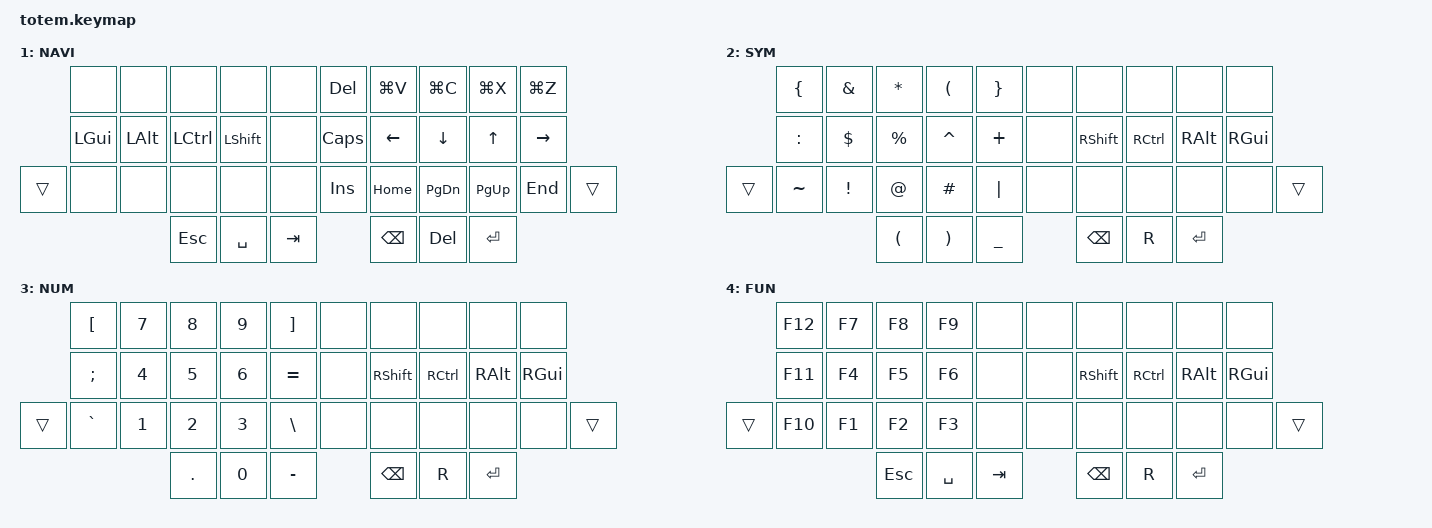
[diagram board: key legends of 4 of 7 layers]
//
//                                                        ▀▀▀▀▀     ▀▀▀▀▀          ▀▀█▀▀
//                                                        ▄▀▀▀▄  ▄  ▄▀▀▀▄  ▄  ▄▀▀▀▄  █  ▄▀▀▀▄
//                                                        █   █  █  █   █  █  █   █  █  █   █
//                                                         ▀▀▀   █   ▀▀▀   █   ▀▀▀   ▀   ▀▀▀
//                                                               █      ▄▄▄█▄▄▄    █   █  
//                                                               ▀      █  █  █     █▄█
//                                                             ▀▀▀▀▀    █  █  █      ▀
//                                                                      ▀  ▀  ▀
//
// ▄▄▄▄▄▄▄▄▄▄▄▄▄▄▄▄▄▄▄▄▄▄▄▄▄▄▄▄▄▄▄▄▄▄▄▄▄▄▄▄▄▄▄▄▄▄▄▄▄▄▄▄▄▄▄▄▄▄▄▄▄▄▄▄▄▄▄▄▄▄▄▄▄▄▄▄▄▄▄▄▄▄▄▄▄▄▄▄▄▄▄▄▄▄▄▄▄▄▄▄▄▄▄▄▄▄▄▄▄▄▄▄▄▄▄▄▄▄▄▄▄▄▄▄▄▄▄▄▄▄▄▄▄▄▄▄▄▄▄▄▄▄▄▄▄▄▄▄▄
       

#include <behaviors.dtsi>
#include <dt-bindings/zmk/keys.h>
#include <dt-bindings/zmk/bt.h>
#include <dt-bindings/zmk/outputs.h>
#define ZMK_POINTING_DEFAULT_MOVE_VAL 1500  // default: 600
#define ZMK_POINTING_DEFAULT_SCRL_VAL 20    // default: 10

#include <dt-bindings/zmk/pointing.h>
// Home row mods macro
#define HRML(k1,k2,k3,k4) &ht LGUI k1 &ht LALT k2  &ht LCTRL k3  &ht LSHFT k4
#define HRMR(k1,k2,k3,k4) &ht RSHFT k1  &ht RCTRL k2  &ht RALT k3  &ht RGUI k4

#define BASE 0
#define NAV  1
#define SYM  2
#define NUM  3
#define FUN  4
#define MOU  5
#define MED  6


/ {
    behaviors {
        ht: hold_tap {
            compatible = "zmk,behavior-hold-tap";
            #binding-cells = <2>;
            flavor = "tap-preferred";
            tapping-term-ms = <220>;
            quick-tap-ms = <150>;
            require-prior-idle-ms = <100>;
            bindings = <&kp>, <&kp>;
        };
    };

    combos {
        compatible = "zmk,combos";
        combo_z {
                timeout-ms = <50>;
                key-positions = <0 1>;
                bindings = <&kp Z>;
        };

        combo_q {
                timeout-ms = <50>;
                key-positions = <1 3>;
                bindings = <&kp Q>;
        };

    };

        keymap {
                compatible = "zmk,keymap";
// ▄▄▄▄▄▄▄▄▄▄▄▄▄▄▄▄▄▄▄▄▄▄▄▄▄▄▄▄▄▄▄▄▄▄▄▄▄▄▄▄▄▄▄▄▄▄▄▄▄▄▄▄▄▄▄▄▄▄▄▄▄▄▄▄▄▄▄▄▄▄▄▄▄▄▄▄▄▄▄▄▄▄▄▄▄▄▄▄▄▄▄▄▄▄▄▄▄▄▄▄▄▄▄▄▄▄▄▄▄▄▄▄▄▄▄▄▄▄▄▄▄▄▄▄▄▄▄▄▄▄▄▄▄▄▄▄▄▄▄▄▄▄▄▄▄▄▄▄▄

                base_layer {
// ┏━━━━━━━━━━━━━━━━━━━━━━━━━━━━━━━━━━━━━━━┓
label= "BASE"                              ;
// ┗━━━━━━━━━━━━━━━━━━━━━━━━━━━━━━━━━━━━━━━┛
//             ┏━━━━━━━━━━━┳━━━━━━━━━━━┳━━━━━━━━━━━┳━━━━━━━━━━━┳━━━━━━━━━━━┓   ┏━━━━━━━━━━━┳━━━━━━━━━━━┳━━━━━━━━━━━┳━━━━━━━━━━━┳━━━━━━━━━━━┓
//             ┃     Q     ┃     W     ┃     F     ┃     P     ┃     G     ┃   ┃     J     ┃     L     ┃     U     ┃     Y     ┃     ;     ┃
//             ┣━━━━━━━━━━━╋━━━━━━━━━━━╋━━━━━━━━━━━╋━━━━━━━━━━━╋━━━━━━━━━━━┫   ┣━━━━━━━━━━━╋━━━━━━━━━━━╋━━━━━━━━━━━╋━━━━━━━━━━━╋━━━━━━━━━━━┫
//             ┃     A     ┃     R     ┃     S     ┃     T     ┃     D     ┃   ┃     H     ┃     N     ┃     E     ┃     I     ┃     O     ┃
// ┏━━━━━━━━━━━╋━━━━━━━━━━━╋━━━━━━━━━━━╋━━━━━━━━━━━╋━━━━━━━━━━━╋━━━━━━━━━━━┫   ┣━━━━━━━━━━━╋━━━━━━━━━━━╋━━━━━━━━━━━╋━━━━━━━━━━━╋━━━━━━━━━━━╋━━━━━━━━━━━┓
// ┃           ┃     Z     ┃     X     ┃     C     ┃     V     ┃     B     ┃   ┃     K     ┃     M     ┃     ,     ┃     .     ┃     /     ┃           ┃
// ┗━━━━━━━━━━━┻━━━━━━━━━━━┻━━━━━━━━━━━╋━━━━━━━━━━━╋━━━━━━━━━━━╋━━━━━━━━━━━┫   ┣━━━━━━━━━━━╋━━━━━━━━━━━╋━━━━━━━━━━━╋━━━━━━━━━━━┻━━━━━━━━━━━┻━━━━━━━━━━━┛
//                                     ┃           ┃    TAB    ┃    SPC    ┃   ┃   ENTER   ┃   BSPC    ┃           ┃
//                                     ┗━━━━━━━━━━━┻━━━━━━━━━━━┻━━━━━━━━━━━┛   ┗━━━━━━━━━━━┻━━━━━━━━━━━┻━━━━━━━━━━━┛
 bindings = <
// ╷           ╷           ╷           ╷           ╷           ╷           ╷   ╷           ╷           ╷           ╷           ╷           ╷           ╷

                &kp X      &kp W      &kp M      &kp G      &kp DQT             &kp HASH       &kp DOT     &kp SQT     &kp J      &kp B
                HRML(S,     C,         N,           T)          &kp K           &kp COMMA      HRMR(A,       E,          I,          H)
    &kp Z       &kp V      &kp P      &kp L      &kp D      &kp FSLH            &kp MINUS      &kp U       &kp O       &kp Y      &kp F   &kp Q
                                        &lt MED ESC     &lt NAV SPC     &kp TAB      &lt SYM BSPC  &lt NUM R    &lt FUN ENTER
                        >;
                };

// ▄▄▄▄▄▄▄▄▄▄▄▄▄▄▄▄▄▄▄▄▄▄▄▄▄▄▄▄▄▄▄▄▄▄▄▄▄▄▄▄▄▄▄▄▄▄▄▄▄▄▄▄▄▄▄▄▄▄▄▄▄▄▄▄▄▄▄▄▄▄▄▄▄▄▄▄▄▄▄▄▄▄▄▄▄▄▄▄▄▄▄▄▄▄▄▄▄▄▄▄▄▄▄▄▄▄▄▄▄▄▄▄▄▄▄▄▄▄▄▄▄▄▄▄▄▄▄▄▄▄▄▄▄▄▄▄▄▄▄▄▄▄▄▄▄▄▄▄▄


                nav_layer {
// ┏━━━━━━━━━━━━━━━━━━━━━━━━━━━━━━━━━━━━━━━┓
label= "NAVI"                              ;
// ┗━━━━━━━━━━━━━━━━━━━━━━━━━━━━━━━━━━━━━━━┛
//             ┏━━━━━━━━━━━┳━━━━━━━━━━━┳━━━━━━━━━━━┳━━━━━━━━━━━┳━━━━━━━━━━━┓   ┏━━━━━━━━━━━┳━━━━━━━━━━━┳━━━━━━━━━━━┳━━━━━━━━━━━┳━━━━━━━━━━━┓
//             ┃           ┃           ┃     UP    ┃           ┃     {     ┃   ┃     }     ┃     7     ┃     8     ┃     9     ┃     +     ┃
//             ┣━━━━━━━━━━━╋━━━━━━━━━━━╋━━━━━━━━━━━╋━━━━━━━━━━━╋━━━━━━━━━━━┫   ┣━━━━━━━━━━━╋━━━━━━━━━━━╋━━━━━━━━━━━╋━━━━━━━━━━━╋━━━━━━━━━━━┫
//             ┃   SHIFT   ┃   LEFT    ┃    DOWN   ┃   RIGHT   ┃     [     ┃   ┃     ]     ┃     4     ┃     5     ┃     6     ┃     -     ┃
// ┏━━━━━━━━━━━╋━━━━━━━━━━━╋━━━━━━━━━━━╋━━━━━━━━━━━╋━━━━━━━━━━━╋━━━━━━━━━━━┫   ┣━━━━━━━━━━━╋━━━━━━━━━━━╋━━━━━━━━━━━╋━━━━━━━━━━━╋━━━━━━━━━━━╋━━━━━━━━━━━┓
// ┃           ┃           ┃   P UP    ┃  C LOCK   ┃  P DOWN   ┃     (     ┃   ┃     )     ┃     1     ┃     2     ┃     3     ┃     *     ┃           ┃
// ┗━━━━━━━━━━━┻━━━━━━━━━━━┻━━━━━━━━━━━╋━━━━━━━━━━━╋━━━━━━━━━━━╋━━━━━━━━━━━┫   ┣━━━━━━━━━━━╋━━━━━━━━━━━╋━━━━━━━━━━━╋━━━━━━━━━━━┻━━━━━━━━━━━┻━━━━━━━━━━━┛
//                                     ┃           ┃    TAB    ┃    SPC    ┃   ┃    DEL    ┃     0     ┃           ┃
//                                     ┗━━━━━━━━━━━┻━━━━━━━━━━━┻━━━━━━━━━━━┛   ┗━━━━━━━━━━━┻━━━━━━━━━━━┻━━━━━━━━━━━┛
 bindings = <
// ╷           ╷           ╷           ╷           ╷           ╷           ╷   ╷           ╷           ╷           ╷           ╷           ╷           ╷

                &none        &none     &none     &none       &none         &kp DEL  &kp LG(V)  &kp LG(C)  &kp LG(X)  &kp LG(Z)
                &kp LGUI   &kp LALT   &kp LCTRL   &kp LSHFT   &none         &kp CAPS   &kp LEFT   &kp DOWN    &kp UP    &kp RIGHT
    &trans      &none        &none     &none     &none       &none         &kp INS     &kp HOME  &kp PG_DN   &kp PG_UP   &kp END &trans      
                                        &kp ESC      &kp SPC      &kp TAB          &kp BSPC     &kp DEL   &kp ENTER      
                        >;
                };

// ▄▄▄▄▄▄▄▄▄▄▄▄▄▄▄▄▄▄▄▄▄▄▄▄▄▄▄▄▄▄▄▄▄▄▄▄▄▄▄▄▄▄▄▄▄▄▄▄▄▄▄▄▄▄▄▄▄▄▄▄▄▄▄▄▄▄▄▄▄▄▄▄▄▄▄▄▄▄▄▄▄▄▄▄▄▄▄▄▄▄▄▄▄▄▄▄▄▄▄▄▄▄▄▄▄▄▄▄▄▄▄▄▄▄▄▄▄▄▄▄▄▄▄▄▄▄▄▄▄▄▄▄▄▄▄▄▄▄▄▄▄▄▄▄▄▄▄▄▄


                sim_layer {
// ┏━━━━━━━━━━━━━━━━━━━━━━━━━━━━━━━━━━━━━━━┓
label= "SYM"                               ;
// ┗━━━━━━━━━━━━━━━━━━━━━━━━━━━━━━━━━━━━━━━┛
//             ┏━━━━━━━━━━━┳━━━━━━━━━━━┳━━━━━━━━━━━┳━━━━━━━━━━━┳━━━━━━━━━━━┓   ┏━━━━━━━━━━━┳━━━━━━━━━━━┳━━━━━━━━━━━┳━━━━━━━━━━━┳━━━━━━━━━━━┓
//             ┃     !     ┃     @     ┃     #     ┃     $     ┃     %     ┃   ┃     ˆ     ┃     &     ┃     Ü     ┃     '     ┃     "     ┃
//             ┣━━━━━━━━━━━╋━━━━━━━━━━━╋━━━━━━━━━━━╋━━━━━━━━━━━╋━━━━━━━━━━━┫   ┣━━━━━━━━━━━╋━━━━━━━━━━━╋━━━━━━━━━━━╋━━━━━━━━━━━╋━━━━━━━━━━━┫
//             ┃     Ä     ┃           ┃    SZ     ┃           ┃           ┃   ┃   MUTE    ┃   YEN     ┃   EURO    ┃  POUND    ┃     Ö     ┃
// ┏━━━━━━━━━━━╋━━━━━━━━━━━╋━━━━━━━━━━━╋━━━━━━━━━━━╋━━━━━━━━━━━╋━━━━━━━━━━━┫   ┣━━━━━━━━━━━╋━━━━━━━━━━━╋━━━━━━━━━━━╋━━━━━━━━━━━╋━━━━━━━━━━━╋━━━━━━━━━━━┓
// ┃           ┃  EMAIL1   ┃  EMAIL2   ┃           ┃           ┃           ┃   ┃   VOL-    ┃   VOL+    ┃   LAST    ┃   NEXT    ┃     \     ┃           ┃
// ┗━━━━━━━━━━━┻━━━━━━━━━━━┻━━━━━━━━━━━╋━━━━━━━━━━━╋━━━━━━━━━━━╋━━━━━━━━━━━┫   ┣━━━━━━━━━━━╋━━━━━━━━━━━╋━━━━━━━━━━━╋━━━━━━━━━━━┻━━━━━━━━━━━┻━━━━━━━━━━━┛
//                                     ┃           ┃    GIF    ┃    ADJ    ┃   ┃           ┃           ┃           ┃
//                                     ┗━━━━━━━━━━━┻━━━━━━━━━━━┻━━━━━━━━━━━┛   ┗━━━━━━━━━━━┻━━━━━━━━━━━┻━━━━━━━━━━━┛
 bindings = <
// ╷           ╷           ╷           ╷           ╷           ╷           ╷   ╷           ╷           ╷           ╷           ╷           ╷           ╷

                &kp LBRC    &kp AMPS   &kp ASTRK   &kp LPAR   &kp RBRC            &none        &none     &none     &none       &none      
                &kp COLON   &kp DLLR  &kp PRCNT   &kp CARET &kp PLUS              &none     &kp RSHFT  &kp RCTRL   &kp RALT   &kp RGUI 
    &trans      &kp TILDE   &kp EXCL     &kp AT     &kp HASH     &kp PIPE         &none        &none     &none     &none       &none   &trans         
                                        &kp LPAR      &kp RPAR      &kp UNDER          &kp BSPC      &kp R    &kp ENTER      
                        >;
                };

// ▄▄▄▄▄▄▄▄▄▄▄▄▄▄▄▄▄▄▄▄▄▄▄▄▄▄▄▄▄▄▄▄▄▄▄▄▄▄▄▄▄▄▄▄▄▄▄▄▄▄▄▄▄▄▄▄▄▄▄▄▄▄▄▄▄▄▄▄▄▄▄▄▄▄▄▄▄▄▄▄▄▄▄▄▄▄▄▄▄▄▄▄▄▄▄▄▄▄▄▄▄▄▄▄▄▄▄▄▄▄▄▄▄▄▄▄▄▄▄▄▄▄▄▄▄▄▄▄▄▄▄▄▄▄▄▄▄▄▄▄▄▄▄▄▄▄▄▄▄


                num_layer {
// ┏━━━━━━━━━━━━━━━━━━━━━━━━━━━━━━━━━━━━━━━┓
label= "NUM"                               ;
// ┗━━━━━━━━━━━━━━━━━━━━━━━━━━━━━━━━━━━━━━━┛
//             ┏━━━━━━━━━━━┳━━━━━━━━━━━┳━━━━━━━━━━━┳━━━━━━━━━━━┳━━━━━━━━━━━┓   ┏━━━━━━━━━━━┳━━━━━━━━━━━┳━━━━━━━━━━━┳━━━━━━━━━━━┳━━━━━━━━━━━┓
//             ┃   RESET   ┃ BT CLEAR  ┃  OUT TOG  ┃           ┃           ┃   ┃           ┃    F7     ┃    F8     ┃    F9     ┃    F12    ┃
//             ┣━━━━━━━━━━━╋━━━━━━━━━━━╋━━━━━━━━━━━╋━━━━━━━━━━━╋━━━━━━━━━━━┫   ┣━━━━━━━━━━━╋━━━━━━━━━━━╋━━━━━━━━━━━╋━━━━━━━━━━━╋━━━━━━━━━━━┫
//             ┃ BOOTLOAD  ┃ BT NEXT   ┃           ┃           ┃           ┃   ┃           ┃    F4     ┃    F5     ┃    F6     ┃    F11    ┃
// ┏━━━━━━━━━━━╋━━━━━━━━━━━╋━━━━━━━━━━━╋━━━━━━━━━━━╋━━━━━━━━━━━╋━━━━━━━━━━━┫   ┣━━━━━━━━━━━╋━━━━━━━━━━━╋━━━━━━━━━━━╋━━━━━━━━━━━╋━━━━━━━━━━━╋━━━━━━━━━━━┓
// ┃           ┃           ┃ BT PREV   ┃           ┃           ┃           ┃   ┃           ┃    F1     ┃    F2     ┃    F3     ┃    F10    ┃           ┃
// ┗━━━━━━━━━━━┻━━━━━━━━━━━┻━━━━━━━━━━━╋━━━━━━━━━━━╋━━━━━━━━━━━╋━━━━━━━━━━━┫   ┣━━━━━━━━━━━╋━━━━━━━━━━━╋━━━━━━━━━━━╋━━━━━━━━━━━┻━━━━━━━━━━━┻━━━━━━━━━━━┛
//                                     ┃           ┃           ┃           ┃   ┃           ┃           ┃           ┃
//                                     ┗━━━━━━━━━━━┻━━━━━━━━━━━┻━━━━━━━━━━━┛   ┗━━━━━━━━━━━┻━━━━━━━━━━━┻━━━━━━━━━━━┛
 bindings = <
// ╷           ╷           ╷           ╷           ╷           ╷           ╷   ╷           ╷           ╷           ╷           ╷           ╷           ╷

                &kp LBKT    &kp N7     &kp N8     &kp N9    &kp RBKT          &none     &none     &none     &none     &none
                &kp SEMI    &kp N4     &kp N5     &kp N6    &kp EQUAL          &none    &kp RSHFT   &kp RCTRL  &kp RALT   &kp RGUI  
    &trans      &kp GRAVE   &kp N1     &kp N2       &kp N3    &kp BSLH          &none     &none     &none     &none     &none     &trans         
                                        &kp DOT      &kp N0      &kp MINUS          &kp BSPC      &kp R      &kp ENTER      
                        >;
                };

                fun_layer {
// ┏━━━━━━━━━━━━━━━━━━━━━━━━━━━━━━━━━━━━━━━┓
label= "FUN"                               ;
// ┗━━━━━━━━━━━━━━━━━━━━━━━━━━━━━━━━━━━━━━━┛
//             ┏━━━━━━━━━━━┳━━━━━━━━━━━┳━━━━━━━━━━━┳━━━━━━━━━━━┳━━━━━━━━━━━┓   ┏━━━━━━━━━━━┳━━━━━━━━━━━┳━━━━━━━━━━━┳━━━━━━━━━━━┳━━━━━━━━━━━┓
//             ┃   RESET   ┃ BT CLEAR  ┃  OUT TOG  ┃           ┃           ┃   ┃           ┃    F7     ┃    F8     ┃    F9     ┃    F12    ┃
//             ┣━━━━━━━━━━━╋━━━━━━━━━━━╋━━━━━━━━━━━╋━━━━━━━━━━━╋━━━━━━━━━━━┫   ┣━━━━━━━━━━━╋━━━━━━━━━━━╋━━━━━━━━━━━╋━━━━━━━━━━━╋━━━━━━━━━━━┫
//             ┃ BOOTLOAD  ┃ BT NEXT   ┃           ┃           ┃           ┃   ┃           ┃    F4     ┃    F5     ┃    F6     ┃    F11    ┃
// ┏━━━━━━━━━━━╋━━━━━━━━━━━╋━━━━━━━━━━━╋━━━━━━━━━━━╋━━━━━━━━━━━╋━━━━━━━━━━━┫   ┣━━━━━━━━━━━╋━━━━━━━━━━━╋━━━━━━━━━━━╋━━━━━━━━━━━╋━━━━━━━━━━━╋━━━━━━━━━━━┓
// ┃           ┃           ┃ BT PREV   ┃           ┃           ┃           ┃   ┃           ┃    F1     ┃    F2     ┃    F3     ┃    F10    ┃           ┃
// ┗━━━━━━━━━━━┻━━━━━━━━━━━┻━━━━━━━━━━━╋━━━━━━━━━━━╋━━━━━━━━━━━╋━━━━━━━━━━━┫   ┣━━━━━━━━━━━╋━━━━━━━━━━━╋━━━━━━━━━━━╋━━━━━━━━━━━┻━━━━━━━━━━━┻━━━━━━━━━━━┛
//                                     ┃           ┃           ┃           ┃   ┃           ┃           ┃           ┃
//                                     ┗━━━━━━━━━━━┻━━━━━━━━━━━┻━━━━━━━━━━━┛   ┗━━━━━━━━━━━┻━━━━━━━━━━━┻━━━━━━━━━━━┛
 bindings = <
// ╷           ╷           ╷           ╷           ╷           ╷           ╷   ╷           ╷           ╷           ╷           ╷           ╷           ╷

                &kp F12       &kp F7     &kp F8       &kp F9       &none           &none       &none       &none       &none      &none
                &kp F11       &kp F4     &kp F5       &kp F6       &none           &none     &kp RSHFT    &kp RCTRL   &kp RALT   &kp RGUI  
    &trans      &kp F10       &kp F1     &kp F2       &kp F3       &none           &none       &none       &none       &none      &none     &trans         
                                        &kp ESC      &kp SPC      &kp TAB          &kp BSPC      &kp R      &kp ENTER      
                        >;
                };

                mouse_layer {
// ┏━━━━━━━━━━━━━━━━━━━━━━━━━━━━━━━━━━━━━━━┓
label= "MOU"                               ;
// ┗━━━━━━━━━━━━━━━━━━━━━━━━━━━━━━━━━━━━━━━┛
//             ┏━━━━━━━━━━━┳━━━━━━━━━━━┳━━━━━━━━━━━┳━━━━━━━━━━━┳━━━━━━━━━━━┓   ┏━━━━━━━━━━━┳━━━━━━━━━━━┳━━━━━━━━━━━┳━━━━━━━━━━━┳━━━━━━━━━━━┓
//             ┃   RESET   ┃ BT CLEAR  ┃  OUT TOG  ┃           ┃           ┃   ┃           ┃    F7     ┃    F8     ┃    F9     ┃    F12    ┃
//             ┣━━━━━━━━━━━╋━━━━━━━━━━━╋━━━━━━━━━━━╋━━━━━━━━━━━╋━━━━━━━━━━━┫   ┣━━━━━━━━━━━╋━━━━━━━━━━━╋━━━━━━━━━━━╋━━━━━━━━━━━╋━━━━━━━━━━━┫
//             ┃ BOOTLOAD  ┃ BT NEXT   ┃           ┃           ┃           ┃   ┃           ┃    F4     ┃    F5     ┃    F6     ┃    F11    ┃
// ┏━━━━━━━━━━━╋━━━━━━━━━━━╋━━━━━━━━━━━╋━━━━━━━━━━━╋━━━━━━━━━━━╋━━━━━━━━━━━┫   ┣━━━━━━━━━━━╋━━━━━━━━━━━╋━━━━━━━━━━━╋━━━━━━━━━━━╋━━━━━━━━━━━╋━━━━━━━━━━━┓
// ┃           ┃           ┃ BT PREV   ┃           ┃           ┃           ┃   ┃           ┃    F1     ┃    F2     ┃    F3     ┃    F10    ┃           ┃
// ┗━━━━━━━━━━━┻━━━━━━━━━━━┻━━━━━━━━━━━╋━━━━━━━━━━━╋━━━━━━━━━━━╋━━━━━━━━━━━┫   ┣━━━━━━━━━━━╋━━━━━━━━━━━╋━━━━━━━━━━━╋━━━━━━━━━━━┻━━━━━━━━━━━┻━━━━━━━━━━━┛
//                                     ┃           ┃           ┃           ┃   ┃           ┃           ┃           ┃
//                                     ┗━━━━━━━━━━━┻━━━━━━━━━━━┻━━━━━━━━━━━┛   ┗━━━━━━━━━━━┻━━━━━━━━━━━┻━━━━━━━━━━━┛
 bindings = <
// ╷           ╷           ╷           ╷           ╷           ╷           ╷   ╷           ╷           ╷           ╷           ╷           ╷           ╷

               &none        &none     &none     &none       &none          &none     &none     &none     &none     &none
                &kp LGUI   &kp LALT   &kp LCTRL   &kp LSHFT   &none            &none   &mmv MOVE_LEFT     &mmv MOVE_DOWN     &mmv MOVE_UP     &mmv MOVE_RIGHT  
    &trans      &none        &none     &none     &none       &none          &none     &msc SCRL_LEFT     &msc SCRL_DOWN     &msc SCRL_UP     &msc SCRL_RIGHT        
                                        &kp ESC      &kp SPC      &kp TAB          &mkp LCLK      &mkp MCLK      &mkp RCLK      
                        >;
                };

                media_layer {
// ┏━━━━━━━━━━━━━━━━━━━━━━━━━━━━━━━━━━━━━━━┓
label= "MED"                               ;
// ┗━━━━━━━━━━━━━━━━━━━━━━━━━━━━━━━━━━━━━━━┛
//             ┏━━━━━━━━━━━┳━━━━━━━━━━━┳━━━━━━━━━━━┳━━━━━━━━━━━┳━━━━━━━━━━━┓   ┏━━━━━━━━━━━┳━━━━━━━━━━━┳━━━━━━━━━━━┳━━━━━━━━━━━┳━━━━━━━━━━━┓
//             ┃   RESET   ┃ BT CLEAR  ┃  OUT TOG  ┃           ┃           ┃   ┃           ┃    F7     ┃    F8     ┃    F9     ┃    F12    ┃
//             ┣━━━━━━━━━━━╋━━━━━━━━━━━╋━━━━━━━━━━━╋━━━━━━━━━━━╋━━━━━━━━━━━┫   ┣━━━━━━━━━━━╋━━━━━━━━━━━╋━━━━━━━━━━━╋━━━━━━━━━━━╋━━━━━━━━━━━┫
//             ┃ BOOTLOAD  ┃ BT NEXT   ┃           ┃           ┃           ┃   ┃           ┃    F4     ┃    F5     ┃    F6     ┃    F11    ┃
// ┏━━━━━━━━━━━╋━━━━━━━━━━━╋━━━━━━━━━━━╋━━━━━━━━━━━╋━━━━━━━━━━━╋━━━━━━━━━━━┫   ┣━━━━━━━━━━━╋━━━━━━━━━━━╋━━━━━━━━━━━╋━━━━━━━━━━━╋━━━━━━━━━━━╋━━━━━━━━━━━┓
// ┃           ┃           ┃ BT PREV   ┃           ┃           ┃           ┃   ┃           ┃    F1     ┃    F2     ┃    F3     ┃    F10    ┃           ┃
// ┗━━━━━━━━━━━┻━━━━━━━━━━━┻━━━━━━━━━━━╋━━━━━━━━━━━╋━━━━━━━━━━━╋━━━━━━━━━━━┫   ┣━━━━━━━━━━━╋━━━━━━━━━━━╋━━━━━━━━━━━╋━━━━━━━━━━━┻━━━━━━━━━━━┻━━━━━━━━━━━┛
//                                     ┃           ┃           ┃           ┃   ┃           ┃           ┃           ┃
//                                     ┗━━━━━━━━━━━┻━━━━━━━━━━━┻━━━━━━━━━━━┛   ┗━━━━━━━━━━━┻━━━━━━━━━━━┻━━━━━━━━━━━┛
 bindings = <
// ╷           ╷           ╷           ╷           ╷           ╷           ╷   ╷           ╷           ╷           ╷           ╷           ╷           ╷

                &none        &none     &none     &none       &none                 &none     &none     &none     &none     &none
                 &kp LGUI   &kp LALT   &kp LCTRL   &kp LSHFT   &none               &none      &kp C_STOP &kp C_PREV  &kp C_VOL_DN &kp C_VOL_UP &kp C_NEXT 
    &trans      &none        &none     &none     &none       &none              &out OUT_TOG     &bt BT_SEL 0 &bt BT_SEL 1 &bt BT_SEL 2 &bt BT_SEL 3     &bt BT_SEL 4         
                                        &kp ESC      &kp SPC      &kp TAB          &kp C_STOP  &kp C_PP &kp C_MUTE        
                        >;
                };
        };
};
